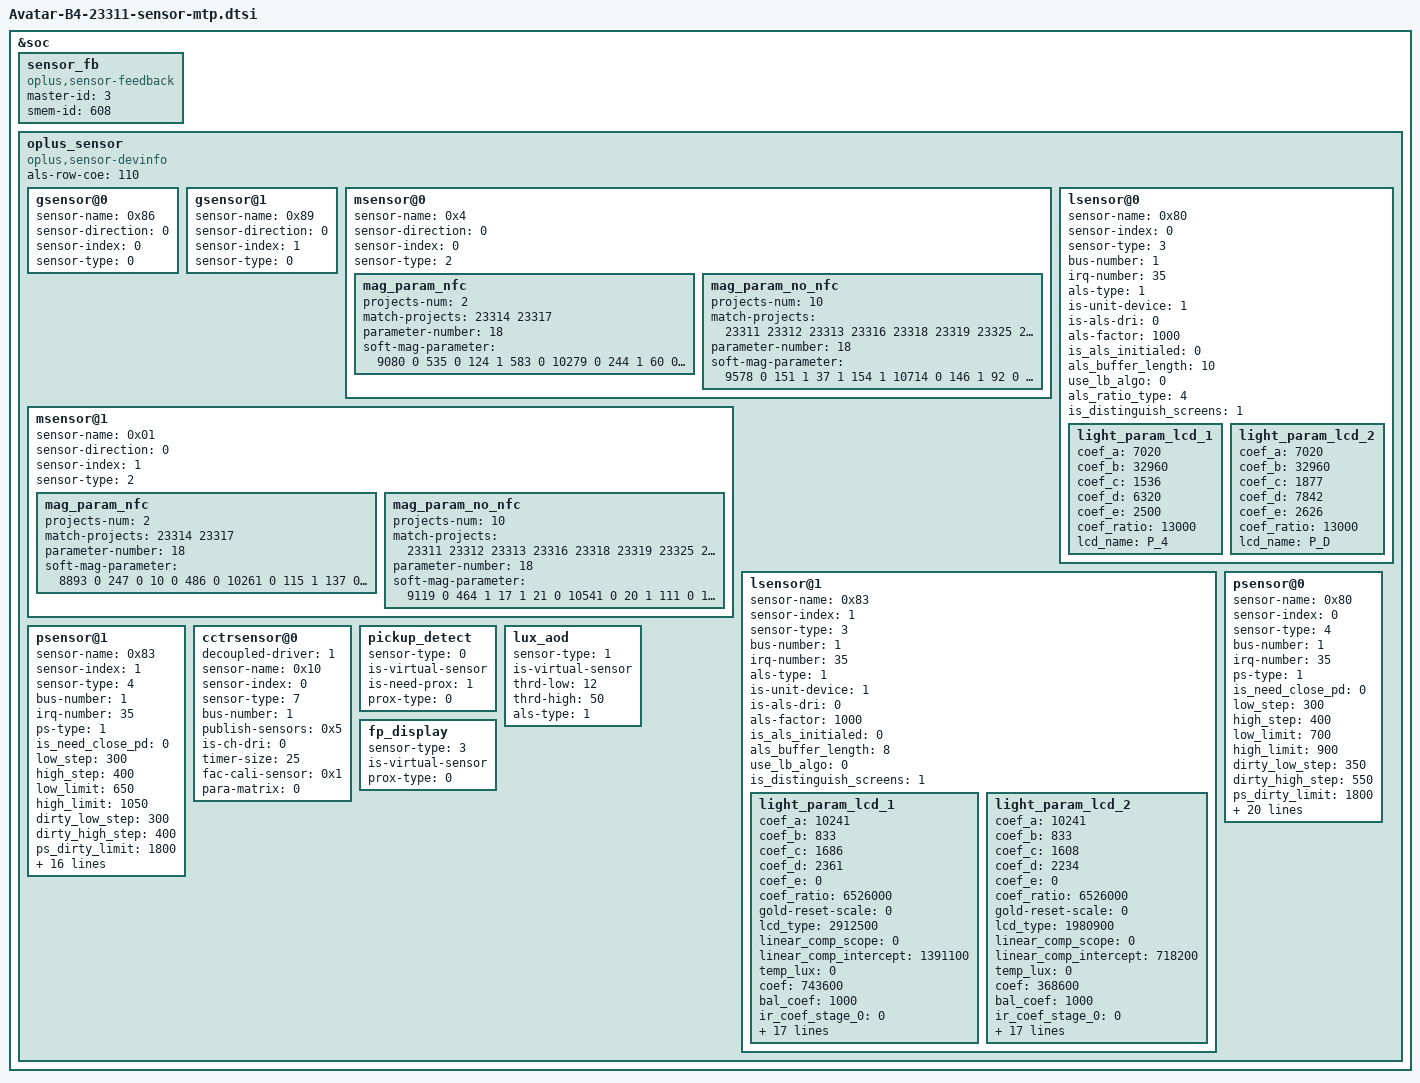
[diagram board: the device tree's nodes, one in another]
&soc {
	sensor_fb: sensor_fb {
		compatible = "oplus,sensor-feedback";
		master-id  = <3>;
		smem-id    = <608>;
	};
	oplus_sensor {
			compatible = "oplus,sensor-devinfo";
			als-row-coe = <110>;
			/*enum {LSM6DSM = 0x01, BMI160 = 0x02, LSM6DS3 = 0x04, BMI260 = 0x08};*/
			gsensor@0 {
					sensor-name = <0x86>;//STK83xx
					sensor-direction = <0>;
					sensor-index = <0>;//source num
					sensor-type = <0>;//OPPO_ACCEL
			};
			gsensor@1 {
					sensor-name = <0x89>;//BMA510
					sensor-direction = <0>;
					sensor-index = <1>;//source num
					sensor-type = <0>;//OPPO_ACCEL
			};
			/* enum {AKM0991X = 0x01, MMC5603 = 0x02, MXG4300 = 0x04};*/
			msensor@0 {
				sensor-name = <0x4>;//MXG4300
				sensor-direction = <0>;
				sensor-index = <0>;
				sensor-type = <2>;//OPLUS_MAG
				mag_param_nfc {
					projects-num = <2>;
					match-projects = <23314 23317>;
					parameter-number= <18>;
					soft-mag-parameter = <9080 0 535 0 124 1 583 0 10279 0 244 1 60 0 105 0 10491 0>;//e00 sign e01 sign...
				};
				mag_param_no_nfc {
					projects-num = <10>;
					match-projects = <23311 23312 23313 23316 23318 23319 23325 23326 23327 23328>;
					parameter-number= <18>;
					soft-mag-parameter = <9578 0 151 1 37 1 154 1 10714 0 146 1 92 0 199 0 10719 0>;//e00 sign e01 sign...
				};
			};
			msensor@1 {
					sensor-name = <0x01>;//Ak09919
					sensor-direction = <0>;
					sensor-index = <1>;
					sensor-type = <2>;//OPLUS_MAG
				mag_param_nfc {
					projects-num = <2>;
					match-projects = <23314 23317>;
					parameter-number= <18>;
					soft-mag-parameter = <8893 0 247 0 10 0 486 0 10261 0 115 1 137 0 297 1 10389 0>;//e00 sign e01 sign...
				};
				mag_param_no_nfc {
					projects-num = <10>;
					match-projects = <23311 23312 23313 23316 23318 23319 23325 23326 23327 23328>;
					parameter-number= <18>;
					soft-mag-parameter = <9119 0 464 1 17 1 21 0 10541 0 20 1 111 0 185 1 10701 0>;//e00 sign e01 sign...
				};
			};
			/*enum {STK3A5X=0x01,TCS3701=0x02,TCS3408=0x04,STK326X=0x08,MN78911=0x10};*/
			/*enum {NORMAL=0x01,UNDER_LCD=0x02,VIRTUAL_UNDER_LCD=0x03}*/
			lsensor@0 {
					sensor-name = <0x80>;//STK3ACX
					sensor-index = <0>;
					sensor-type = <3>;//OPLUS_ALS
					bus-number = <1>;
					irq-number = <35>;
					als-type = <1>;//NORMAL_LCD
					is-unit-device = <1>;
					is-als-dri = <0>;
					als-factor = <1000>;
					is_als_initialed = <0>;
					als_buffer_length = <10>;
					//normalization_value = <549>;
					use_lb_algo = <0>;
					als_ratio_type = <4>; // use for stk33502 to split light, <0:type old; 1:type abcde; 2:type accordance>
					is_distinguish_screens = <1>;
				light_param_lcd_1 {
					coef_a     = <7020>;
					coef_b     = <32960>;
					coef_c     = <1536>;
					coef_d     = <6320>;
					coef_e     = <2500>;
					coef_ratio = <13000>;
					lcd_name = "P_4";
				};
				light_param_lcd_2 {
					coef_a     = <7020>;
					coef_b     = <32960>;
					coef_c     = <1877>;
					coef_d     = <7842>;
					coef_e     = <2626>;
					coef_ratio = <13000>;
					lcd_name = "P_D";
				};
			};
			lsensor@1 {
					sensor-name = <0x83>;//SIP3511
					sensor-index = <1>;
					sensor-type = <3>;//OPLUS_ALS
					bus-number = <1>;
					irq-number = <35>;
					als-type = <1>;//NORMAL_LCD
					is-unit-device = <1>;
					is-als-dri = <0>;
					als-factor = <1000>;
					is_als_initialed = <0>;
					als_buffer_length = <8>;
					//normalization_value = <549>;
					use_lb_algo = <0>;
					is_distinguish_screens = <1>;
				light_param_lcd_1 {
					coef_a     = <10241>;
					coef_b     = <833>;
					coef_c     = <1686>;
					coef_d     = <2361>;
					coef_e     = <0>;
					coef_ratio = <6526000>;
					gold-reset-scale = <0>;
					lcd_type = <2912500>;
					linear_comp_scope = <0>;
					linear_comp_intercept = <1391100>;
					temp_lux = <0>;
					coef = <743600>;
					bal_coef = <1000>;
					ir_coef_stage_0 = <0>;
					ir_coef_stage_1 = <0>;
					ir_coef_stage_2 = <1000>;
					ir_coef_stage_3 = <0>;
					ir_coef_val_0 = <0>;
					ir_coef_val_1 = <1000>;
					ir_coef_val_2 = <0>;
					ir_coef_val_3 = <0>;
					ir_coef_val_4 = <848>;
					polling_use_majority = <557>;
					k43 = <95>;
					k51 = <1000>;
					k52 = <0>;
					k53 = <0>;
					k61 = <841>;
					k62 = <462>;
					k63 = <43>;
					lcd_name = "P_4";
				};
				light_param_lcd_2 {
					coef_a     = <10241>;
					coef_b     = <833>;
					coef_c     = <1608>;
					coef_d     = <2234>;
					coef_e     = <0>;
					coef_ratio = <6526000>;
					gold-reset-scale = <0>;
					lcd_type = <1980900>;
					linear_comp_scope = <0>;
					linear_comp_intercept = <718200>;
					temp_lux = <0>;
					coef = <368600>;
					bal_coef = <1000>;
					ir_coef_stage_0 = <0>;
					ir_coef_stage_1 = <0>;
					ir_coef_stage_2 = <1000>;
					ir_coef_stage_3 = <0>;
					ir_coef_val_0 = <0>;
					ir_coef_val_1 = <1000>;
					ir_coef_val_2 = <0>;
					ir_coef_val_3 = <0>;
					ir_coef_val_4 = <1087>;
					polling_use_majority = <914>;
					k43 = <40>;
					k51 = <1000>;
					k52 = <0>;
					k53 = <0>;
					k61 = <1072>;
					k62 = <906>;
					k63 = <43>;
					lcd_name = "P_D";
				};
			};
			psensor@0 {
					sensor-name = <0x80>;//STK3ACX
					sensor-index = <0>;
					sensor-type = <4>;//OPLUS_PROXIMITY
					bus-number = <1>;
					irq-number = <35>;
					//ps-cail-type = <2>;
					ps-type = <1>;
					/*1-need close 2-close has contidition 0-not close*/
					is_need_close_pd = <0>;
					//is_ps_initialzed = <0>;
					low_step = <300>;
					high_step = <400>;
					low_limit = <700>;
					high_limit = <900>;
					dirty_low_step = <350>;
					dirty_high_step = <550>;
					ps_dirty_limit = <1800>;
					ps_ir_limit = <2000>;
					ps_adjust_min = <0>;
					ps_adjust_max = <1850>;
					sampling_count = <5>;
					step_max = <400>;
					step_min = <100>;
					step_div = <2000>;
					anti_shake_delta = <70>;
					dynamic_cali_max = <5000>;
					raw2offset_radio = <1000>;
					offset_max = <60000>;
					offset_range_min = <0>;
					offset_range_max = <65535>;
					force_cali_limit = <2000>;
					cali_jitter_limit = <30>;
					cal_offset_margin = <3000>;
					esd_gpio_use = <1>;
					parameter-number = <8>;
					sensor-reg = <0x01 0x43
							0x03 0x2C
							0x4E 0x60
							0xDB 0x00>; //override special reg
					/*sensor-reg end*/
			};
			psensor@1 {
					sensor-name = <0x83>;//SIP3511
					sensor-index = <1>;
					sensor-type = <4>;//OPLUS_PROXIMITY
					bus-number = <1>;
					irq-number = <35>;
					//ps-cail-type = <2>;
					ps-type = <1>;
					/*1-need close 2-close has contidition 0-not close*/
					is_need_close_pd = <0>;
					//is_ps_initialzed = <0>;
					low_step = <300>;
					high_step = <400>;
					low_limit = <650>;
					high_limit = <1050>;
					dirty_low_step = <300>;
					dirty_high_step = <400>;
					ps_dirty_limit = <1800>;
					ps_ir_limit = <2000>;
					ps_adjust_min = <0>;
					ps_adjust_max = <1850>;
					sampling_count = <5>;
					step_max = <400>;
					step_min = <100>;
					step_div = <2000>;
					anti_shake_delta = <70>;
					dynamic_cali_max = <2000>;
					raw2offset_radio = <1000>;
					offset_max = <60000>;
					offset_range_min = <0>;
					offset_range_max = <65534>;
					force_cali_limit = <2000>;
					cali_jitter_limit = <30>;
					cal_offset_margin = <3000>;
			};
			cctrsensor@0 {
				decoupled-driver = <1>; //0 - tcs3408 driver; 1 - oplus_cct driver
				sensor-name = <0x10>; //sip1221lr1n
				sensor-index = <0>;
				sensor-type = <7>; //OPLUS_CCT_REAR
				bus-number = <1>;
				//feature
				publish-sensors = <0x5>; //bit[0] - als, bit[1] - rgb, bit[2] - flicker, bit[3] - spectral
				is-ch-dri = <0>;
				timer-size = <25>; //ms
				fac-cali-sensor = <0x1>; //0x1 - als, 0x2 - rgb, 0x4, flicker
				para-matrix = <0>;//0-default
			};
			/*virtual sensor
			enum sensor_algo_id {
					OPLUS_PICKUP_DETECT,
					OPLUS_LUX_AOD,
					OPLUS_TP_GESTURE,
					OPLUS_FP_DISPLAY,
					OPLUS_FREE_FALL,
					OPLUS_CAMERA_PROTECT,
					SENSOR_ALGO_NUM
			}*/
			pickup_detect {
					sensor-type = <0>; //OPLUS_PICKUP_DETECT
					is-virtual-sensor;
					is-need-prox = <1>;
					prox-type = <0>; // 0 - proximity; 1 - proximity_fake
			};
			lux_aod {
					sensor-type = <1>; //OPLUS_LUX_AOD
					is-virtual-sensor;
					thrd-low = <12>;
					thrd-high = <50>;
					als-type = <1>; // 0 - wise_light; 1 - ambient_light
			};
			fp_display {
					sensor-type = <3>; //OPLUS_FP_DISPLAY
					is-virtual-sensor;
					prox-type = <0>; // 0 - proximity; 1 - proximity_fake
			};
	};
};
